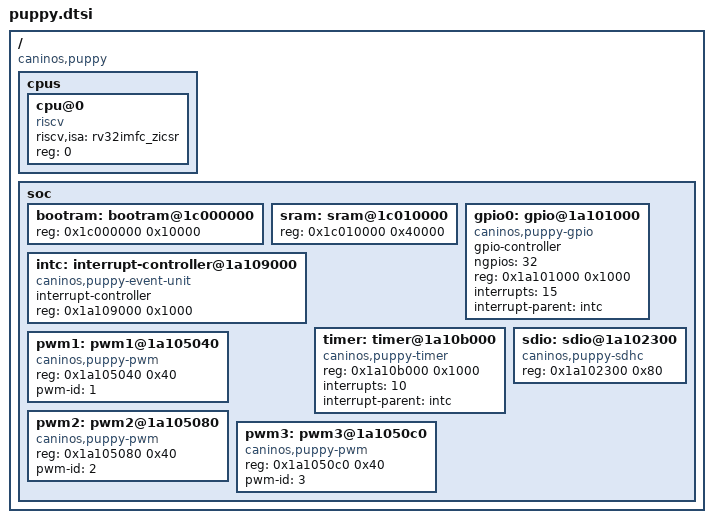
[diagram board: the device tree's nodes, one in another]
/dts-v1/;

#include "zephyr/dt-bindings/gpio/gpio.h"

/ {
	#address-cells = <1>;
	#size-cells = <1>;
	compatible = "caninos,puppy";

	cpus {
		#address-cells = <1>;
		#size-cells = <0>;

		cpu@0 {
			device_type = "cpu";
			status = "okay";
			compatible = "riscv";
			riscv,isa = "rv32imfc_zicsr";
			reg = <0>;
		};
	};

	soc: soc {
		#address-cells = <0x01>;
		#size-cells = <0x01>;

		bootram: bootram@1c000000 {
			device_type = "memory";
			reg = <0x1c000000 0x10000>;
			status="okay";
		};

		sram: sram@1c010000 {
			device_type = "memory";
			reg = <0x1c010000 0x40000>;
			status="okay";
		};

		gpio0: gpio@1a101000 {
			compatible = "caninos,puppy-gpio";
			gpio-controller;
			ngpios = <32>;
			reg = <0x1a101000 0x1000>;
			interrupts = <15>;
			interrupt-parent = <&intc>;
			#gpio-cells = <2>;
		};

		intc: interrupt-controller@1a109000 {
			#interrupt-cells = <1>;
			compatible = "caninos,puppy-event-unit";
			interrupt-controller;
			reg = <0x1a109000 0x1000>;
		};

		timer: timer@1a10b000 {
			compatible = "caninos,puppy-timer";
			reg = <0x1a10b000 0x1000>;
			interrupts = <10>;
			interrupt-parent = <&intc>;
		};

		/* PWM0 is not externalized on chip */

		pwm1: pwm1@1a105040 {
			compatible = "caninos,puppy-pwm";
			reg = <0x1a105040 0x40>;
			pwm-id = <1>;
			#pwm-cells = <3>;
		};

		pwm2: pwm2@1a105080 {
			compatible = "caninos,puppy-pwm";
			reg = <0x1a105080 0x40>;
			pwm-id = <2>;
			#pwm-cells = <3>;
		};

		pwm3: pwm3@1a1050c0 {
			compatible = "caninos,puppy-pwm";
			reg = <0x1a1050c0 0x40>;
			pwm-id = <3>;
			#pwm-cells = <3>;
		};

		sdio: sdio@1a102300 {
			compatible = "caninos,puppy-sdhc";
			reg = <0x1a102300 0x80>;
		};
	};
};
